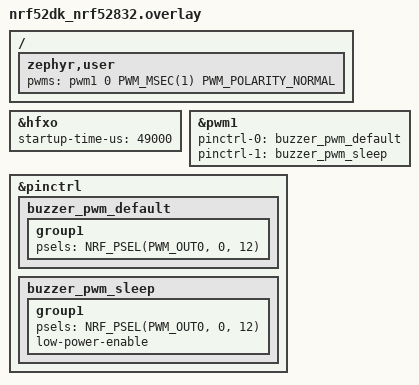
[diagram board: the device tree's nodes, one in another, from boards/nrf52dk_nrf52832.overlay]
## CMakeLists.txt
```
#
# Copyright (c) 2018 Nordic Semiconductor
#
# SPDX-License-Identifier: LicenseRef-Nordic-5-Clause
#
cmake_minimum_required(VERSION 3.20.0)

find_package(Zephyr REQUIRED HINTS $ENV{ZEPHYR_BASE})
project(NONE)

# NORDIC SDK APP START
target_sources(app PRIVATE
  src/main.c
  src/Beacon.c
  src/rssi_filter.c
  src/distance_manager.c
  src/buzzer.c
)

# NORDIC SDK APP END
zephyr_library_include_directories(.)
```

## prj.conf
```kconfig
#
# Copyright (c) 2018 Nordic Semiconductor
#
# SPDX-License-Identifier: LicenseRef-Nordic-5-Clause
#

# Button and LED library
CONFIG_DK_LIBRARY=y

# Bluetooth LE
CONFIG_BT=y
CONFIG_BT_PERIPHERAL=y
CONFIG_BT_SMP=y

# Standard Battery Service (Battery Service 0x180F / Battery Level 0x2A19).
# The Zephyr built-in implementation is used rather than a hand-written set of
# GATT attributes: the service is defined in
# zephyr/subsys/bluetooth/services/bas/bas.c:75-93 and mounted automatically by
# SYS_INIT (same file, :140), so the application only has to call
# bt_bas_set_battery_level(). The payoff is that Battery Level carries the READ
# property -- a phone can read it without subscribing -- and nRF Connect shows
# "Battery Service / Battery Level" instead of "Unknown Characteristic".
CONFIG_BT_BAS=y

# RSSI queries. Under the SoftDevice Controller the dispatch of HCI Read RSSI
# (opcode 0x1405) is gated on this symbol: with it off the opcode falls through
# to the default branch and the controller answers BT_HCI_ERR_UNKNOWN_CMD, so
# every bt_hci_cmd_send_sync() call fails.
# Evidence: nrf/subsys/bluetooth/controller/hci_internal.c:932-944 (command
# dispatch) and :371-372 in the same file (hci_read_rssi in the supported-
# commands bitmap reported to the host).
# The symbol defaults to off and must be set explicitly; changing it requires a
# full rebuild so the SDC glue is recompiled.
CONFIG_BT_CTLR_CONN_RSSI=y

# Fixed pairing passkey, supplied by CONFIG_BT_APP_PASSKEY plus the
# bt_conn_auth_cb.app_passkey callback. The older route,
# CONFIG_BT_FIXED_PASSKEY + bt_passkey_set(), is deprecated. The two are mutually
# exclusive (BT_APP_PASSKEY depends on !BT_FIXED_PASSKEY), so this is a whole-
# or-nothing replacement.
CONFIG_BT_APP_PASSKEY=y
CONFIG_BT_DEVICE_NAME="Tracker Beacon"

# Enable PHY updates.
CONFIG_BT_USER_PHY_UPDATE=y

# ADC enable.
CONFIG_NRFX_SAADC=y

# Increase stack size for the main thread and the system workqueue.
CONFIG_SYSTEM_WORKQUEUE_STACK_SIZE=2048
CONFIG_MAIN_STACK_SIZE=2048
CONFIG_BT_RX_STACK_SIZE=2048

# Data Length and MTU
CONFIG_BT_USER_DATA_LEN_UPDATE=y
CONFIG_BT_CTLR_DATA_LENGTH_MAX=251
CONFIG_BT_BUF_ACL_RX_SIZE=251
CONFIG_BT_BUF_ACL_TX_SIZE=251
CONFIG_BT_L2CAP_TX_MTU=247
CONFIG_BT_GATT_CLIENT=y

# Reboot on disconnect: the translation unit implementing sys_reboot() is only
# compiled in when CONFIG_REBOOT=y (zephyr/lib/os/CMakeLists.txt).
CONFIG_REBOOT=y

# Power management.
CONFIG_PM=y
CONFIG_PM_DEVICE=y
CONFIG_PM_DEVICE_RUNTIME=y

# The buzzer is driven through PWM. Only the PWM subsystem has to be enabled:
# CONFIG_PWM_NRFX is selected automatically from the devicetree, because its
# Kconfig says "default y / depends on DT_HAS_NORDIC_NRF_PWM_ENABLED" and the
# board overlay sets pwm1 to okay.
CONFIG_PWM=y

# MPSL assertion handling. The default implementation truncates the file name to
# 10 characters, printk()s it to the UART and calls k_oops(); on this board UART0
# is not routed to the J-Link VCOM, so that message is never seen. With this
# enabled the application-supplied mpsl_assert_handle(file, line) takes over and
# receives the full path and line number (see main.c).
CONFIG_MPSL_ASSERT_HANDLER=y
```

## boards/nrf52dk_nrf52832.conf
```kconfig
#
# nRF52 DK (nRF52832) board configuration
#

# ---------------------------------------------------------------------------
# Console
# ---------------------------------------------------------------------------
# The nRF52 DK has an on-board VCOM, and the console uses UART0 (P0.06 TX /
# P0.08 RX), which the board's nrf52dk_nrf52832_defconfig already provides:
#     CONFIG_SERIAL=y  CONFIG_CONSOLE=y  CONFIG_UART_CONSOLE=y
# Nothing here needs to redirect the console to USB CDC ACM: the nRF52832 has no
# USB peripheral at all, so such an overlay would fail devicetree parsing.
CONFIG_UART_INTERRUPT_DRIVEN=y

# ---------------------------------------------------------------------------
# Battery monitoring: the nrfx SAADC driver (CONFIG_NRFX_SAADC lives in prj.conf).
# CONFIG_ADC must stay off, or Zephyr's adc_nrfx_saadc.c would contend with the
# hand-written nrfx_saadc_init() in main.c for the same peripheral (double
# IRQ_CONNECT, double init).
# ---------------------------------------------------------------------------

# ---------------------------------------------------------------------------
# Logging: deliberately off
# ---------------------------------------------------------------------------
# CONFIG_LOG is not enabled: the project does not use the log subsystem, and on an
# nRF52832 with 64 KB of RAM it would only consume space. printk() goes to the
# console directly and needs none of it. Uncomment the three lines below to turn
# logging on while debugging.
#
# CONFIG_LOG=y
# CONFIG_LOG_MODE_DEFERRED=y
# CONFIG_LOG_BACKEND_UART=y
```

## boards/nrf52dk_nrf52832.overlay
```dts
/*
 * Board devicetree corrections: HFXO cold-start time.
 *
 * This board's 32 MHz crystal takes roughly 24.5 ms between TASKS_HFCLKSTART and
 * EVENTS_HFCLKSTARTED, while the SoC devicetree declares 1400 us.
 *
 * MPSL uses that value as the upper bound on how long it is willing to wait after
 * requesting HFCLK:
 *   z_nrf_clock_bt_ctlr_hf_get_startup_time_us()
 *       -> DT_PROP(DT_NODELABEL(hfxo), startup_time_us)   [clock_control_nrf.c:451-454]
 *   mpsl_clock_hfclk_latency_set(...)                     [mpsl/init/mpsl_init.c:457]
 * With 1400 us far below the real 24.5 ms, MPSL gives up waiting and raises
 * "MPSL ASSERT: 5, 1013"; advertising never starts.
 *
 * Where 49000 us comes from (NCS's own Kconfig text,
 * nrf/subsys/mpsl/init/Kconfig:91-96):
 *   "measure the startup time. Set MPSL_HFCLK_LATENCY as twice this number
 *    to account for temperature and supply variations.
 *    On nRF52 and nRF53 Series devices, the startup time corresponds
 *    to the time between TASKS_HFCLKSTART and EVENTS_HFCLKSTARTED."
 *   -> 2 x 24500 us = 49000 us
 *
 * CONFIG_MPSL_HFCLK_LATENCY in prj.conf is not an alternative: the nRF52832
 * devicetree does have an hfxo node, so mpsl_init.c:456 and mpsl_clock_ctrl.c:561
 * take the devicetree branch and that Kconfig symbol is bypassed entirely on this
 * platform.
 *
 * startup_time_us is a uint16_t in MPSL (mpsl_clock.h:439), so the ceiling is
 * 65535 us; 49000 is within range.
 */
&hfxo {
	startup-time-us = <49000>;
};

/*
 * Buzzer on P0.12 (active HIGH), driven by PWM1 channel 0.
 *
 * Polarity is active HIGH, not active LOW, as the schematic confirms: the MCU pin
 * drives the base of NPN transistor Q1 (2N3904) through R11, with R12 10K pulling
 * the base to ground; emitter to ground, collector to the buzzer LS1 and then
 * VCC3.3. That is a classic low-side switch:
 *   base high -> Q1 conducts -> collector pulled to ground -> 3.3 V across the
 *                buzzer -> sound
 *   base low  -> Q1 off -> no current -> silent
 * So pin high = sound and pin low = silence.
 *
 * Why PWM rather than GPIO: the requirement asks for the alarm rhythm to be
 * produced through the Zephyr PWM API, and it keeps open the option of swapping in
 * a *passive* buzzer later by driving a 2..4 kHz square wave directly -- GPIO
 * cannot produce a square wave, PWM can. This board carries an *active* buzzer:
 * it has its own oscillator, so neither the frequency nor the duty cycle of the
 * waveform changes its pitch, and PWM is used here only to express "sound / no
 * sound" plus the rhythm. See buzzer.c for the driver-level constraints.
 *
 * Why pwm1 and not pwm0: the board DTS (nrf52dk_nrf52832.dts:196-201) already
 * enables pwm0 and hands it to pwmleds (P0.17). pwm1 is disabled by default and
 * is enabled here, so the two do not interfere.
 *
 * P0.12 can only have one owner, which is why this file declares no buzzer-gpios
 * and main.c configures no GPIO for it: otherwise GPIO and PWM would drive the
 * same pin at once.
 *
 * The pinctrl groups mirror the board's pwm0 (nrf52dk_nrf52832-pinctrl.dtsi:61-73)
 * except for nordic,invert, which must NOT be copied:
 *   default -- the pin is configured as an OUTPUT with a LOW idle level
 *     (pinctrl_nrf.c:337-341 sets dir to OUTPUT, :575-577 writes the result of
 *     NRF_GET_INVERT; without nordic,invert that is a low level). For this board's
 *     active-high buzzer, idle low means silent, which is exactly the wanted
 *     power-on state. Adding the property would pull the base high the moment
 *     pinctrl is applied and produce a chirp.
 *   sleep -- low-power-enable forces the pin to an INPUT and disconnects it (same
 *     file :580-583). The base is then pulled to ground by R12 and Q1 is off, so
 *     it stays silent while asleep too.
 *
 * The driver has a build-time check, NRF_DT_CHECK_NODE_HAS_PINCTRL_SLEEP
 * (pwm_nrfx.c:416), so pinctrl-1 plus "sleep" is mandatory, not just default.
 */
&pwm1 {
	status = "okay";
	pinctrl-0 = <&buzzer_pwm_default>;
	pinctrl-1 = <&buzzer_pwm_sleep>;
	pinctrl-names = "default", "sleep";
};

&pinctrl {
	buzzer_pwm_default: buzzer_pwm_default {
		group1 {
			/* nordic,invert is deliberately absent here: an active-high
			 * buzzer needs a LOW idle level. */
			psels = <NRF_PSEL(PWM_OUT0, 0, 12)>;
		};
	};

	buzzer_pwm_sleep: buzzer_pwm_sleep {
		group1 {
			psels = <NRF_PSEL(PWM_OUT0, 0, 12)>;
			low-power-enable;
		};
	};
};

/ {
	zephyr,user {
		/* The property name must be an unprefixed pwms, not buzzer-pwms.
		 * Of all property kinds only gpio and io-channel are exempt from
		 * the prefix rule (edtlib.py:2072-2085); everything else uses
		 * prop.name[:-1] as the specifier space, so buzzer-pwms would
		 * demand a #buzzer-pwm-cells declaration from the controller --
		 * and pwm1 in nrf52832.dtsi:449 only has the standard
		 * #pwm-cells = <3>. dtc would fail outright with
		 * "lacks #buzzer-pwm-cells". (That is also why an earlier
		 * buzzer-gpios could carry a prefix.)
		 *
		 * The polarity is PWM_POLARITY_NORMAL because the buzzer is
		 * active high (low-side NPN):
		 *   0% duty   -> constant INACTIVE level -> pin low  -> silent
		 *   100% duty -> constant ACTIVE level   -> pin high -> sound
		 * That contract is written down in pwm.h:596-599, and the driver
		 * matches it in pwm_nrfx.c:199-207 and :238-249; it is not an
		 * invention of this project.
		 *
		 * PWM_POLARITY_INVERTED must NOT be used: it would treat
		 * active-high hardware as active low, so writing "silent" would
		 * drive the pin high and sound the buzzer continuously. It has to
		 * be omitted in both places -- the pinctrl group above and here --
		 * since removing only one leaves the other still inverting.
		 *
		 * The polarity cell cannot be omitted: pwm1 has
		 * #pwm-cells = <3> (nrf52832.dtsi:449), so channel, period and
		 * flags are all required after the phandle or dtc reports
		 * "missing data after phandle". PWM_POLARITY_NORMAL is 0
		 * (dt-bindings/pwm/pwm.h), i.e. "do not invert".
		 *
		 * The period is 1 ms (16000 cycles of 16 MHz, below the COUNTERTOP
		 * ceiling of 32767). In DC mode (0% / 100%) the driver never
		 * validates the period at all; a legal value is given so that
		 * producing a real 2..4 kHz square wave later needs only a period
		 * change here, with no module code touched. */
		pwms = <&pwm1 0 PWM_MSEC(1) PWM_POLARITY_NORMAL>;
	};
};
```

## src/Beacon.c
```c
/*
 * Copyright (c) 2018 Nordic Semiconductor ASA
 *
 * SPDX-License-Identifier: LicenseRef-Nordic-5-Clause
 */

#include <zephyr/types.h>
#include <stddef.h>
#include <errno.h>
#include <zephyr/kernel.h>
#include <zephyr/bluetooth/bluetooth.h>
#include <zephyr/bluetooth/conn.h>
#include <zephyr/bluetooth/uuid.h>
#include <zephyr/bluetooth/gatt.h>

#include "Beacon.h"

static bool indicate_enabled;
static bool button_state;
static struct my_lbs_cb lbs_cb;

/* ==================== The "password" behind the lost-item ring ====================
 *
 * The passkey is NOT stored by this file: it is the *link-layer pairing
 * passkey*, supplied by auth_app_passkey() in main.c. Of the writable
 * characteristics, only the Ring one carries BT_GATT_PERM_WRITE_AUTHEN. The LED
 * one carries plain BT_GATT_PERM_WRITE on purpose: switching the LED must not
 * trigger pairing, because pairing is what arms the buzzer.
 *
 * For the Ring characteristic, gatt.c:3105-3109 (NCS v3.4.0) says of the
 * authentication permission mask:
 *
 *     if (mask & BT_GATT_PERM_AUTHEN_MASK) {
 *             if (bt_conn_get_security(conn) < BT_SECURITY_L3) {
 *                     return BT_ATT_ERR_AUTHENTICATION;
 *             }
 *     }
 *
 * In other words write_ring() is invoked only while the link is authenticated
 * (>= L3). If the peer has not paired yet, the stack answers with an
 * authentication error, the phone prompts for the passkey, and once pairing
 * completes att_req_retry() (att.c:3306-3315) resends the same request -- which
 * is why the user sees "enter the passkey and the write just succeeds" without
 * tapping twice.
 *
 * Note that pairing is per *link*, not per characteristic: once the peer pairs
 * for the Ring characteristic, every AUTHEN attribute on that link is usable.
 * The LED does not use a second password; it is simply outside the gate.
 *
 * So write_ring() does not need a lock check of its own. It also does not
 * interpret the value beyond 0/1: main.c decides that 1 rings and re-arms the
 * buzzer while 0 stops the ring and mutes all alarms.
 *
 * Concrete link-layer line numbers drift between SDK releases; they are quoted
 * here against nRF Connect SDK v3.4.0. */

static struct bt_gatt_indicate_params ind_params;

static void mylbsbc_ccc_cfg_changed(const struct bt_gatt_attr *attr, uint16_t value)
{
	indicate_enabled = (value == BT_GATT_CCC_INDICATE);
}

/* Called once a remote device has acknowledged the indication at its host layer. */

static void indicate_cb(struct bt_conn *conn, struct bt_gatt_indicate_params *params, uint8_t err)
{
	ARG_UNUSED(conn);
	ARG_UNUSED(params);
	ARG_UNUSED(err);
}

static ssize_t write_led(struct bt_conn *conn, const struct bt_gatt_attr *attr, const void *buf,
			 uint16_t len, uint16_t offset, uint8_t flags)
{
	ARG_UNUSED(conn);
	ARG_UNUSED(attr);
	ARG_UNUSED(flags);

	if (len != 1U) {
		return BT_GATT_ERR(BT_ATT_ERR_INVALID_ATTRIBUTE_LEN);
	}

	if (offset != 0) {
		return BT_GATT_ERR(BT_ATT_ERR_INVALID_OFFSET);
	}

	if (lbs_cb.led_cb) {
		uint8_t val = *((uint8_t *)buf);

		if (val == 0x00 || val == 0x01) {
			lbs_cb.led_cb(val ? true : false);
		} else {
			return BT_GATT_ERR(BT_ATT_ERR_VALUE_NOT_ALLOWED);
		}
	}

	return len;
}

/* Write the ring switch (one byte, 0 or 1).
 *
 * 1 = start the lost-item ring and re-arm the buzzer; 0 = stop the ring and
 * mute every alarm, including the automatic RSSI distance beeping, until a 1
 * is written again. The application-side latch lives in main.c, so this layer
 * stays free of buzzer knowledge.
 *
 * There is deliberately no "is it unlocked" test here. The characteristic's
 * permission is BT_GATT_PERM_WRITE_AUTHEN, and gatt.c:3105-3109 guarantees such
 * a write callback runs only when bt_conn_get_security(conn) >=
 * BT_SECURITY_L3, i.e. the peer has paired and authenticated. Reaching this
 * function therefore already means the passkey was accepted; testing it again
 * would be redundant. See the comment block at the top of this file. */
static ssize_t write_ring(struct bt_conn *conn, const struct bt_gatt_attr *attr, const void *buf,
			  uint16_t len, uint16_t offset, uint8_t flags)
{
	uint8_t val;

	ARG_UNUSED(conn);
	ARG_UNUSED(attr);
	ARG_UNUSED(flags);

	if (offset != 0U) {
		return BT_GATT_ERR(BT_ATT_ERR_INVALID_OFFSET);
	}

	if (len != 1U) {
		return BT_GATT_ERR(BT_ATT_ERR_INVALID_ATTRIBUTE_LEN);
	}

	val = *(const uint8_t *)buf;
	if (val > 1U) {
		return BT_GATT_ERR(BT_ATT_ERR_VALUE_NOT_ALLOWED);
	}

	if (lbs_cb.ring_cb) {
		lbs_cb.ring_cb(val ? true : false);
	}

	return (ssize_t)len;
}

static ssize_t read_button(struct bt_conn *conn, const struct bt_gatt_attr *attr, void *buf,
			   uint16_t len, uint16_t offset)
{
	/* attr->user_data points at button_state, the pointer handed to
	 * BT_GATT_CHARACTERISTIC(..., &button_state). It is taken as a bool* and
	 * not a char* so that sizeof(*value) matches the type: both are 1 today,
	 * so the number of bytes on the wire is unchanged, but this removes the
	 * trap where a change of type for button_state would silently truncate.
	 */
	const bool *value = attr->user_data;

	if (lbs_cb.button_cb) {
		button_state = lbs_cb.button_cb();
		return bt_gatt_attr_read(conn, attr, buf, len, offset, value, sizeof(*value));
	}

	return 0;
}

/* LED Button Service Declaration */
BT_GATT_SERVICE_DEFINE(
	my_lbs_svc, BT_GATT_PRIMARY_SERVICE(BT_UUID_LBS),
	BT_GATT_CHARACTERISTIC(BT_UUID_LBS_BUTTON, BT_GATT_CHRC_READ | BT_GATT_CHRC_INDICATE,
			       BT_GATT_PERM_READ_AUTHEN, read_button, NULL, &button_state),
	BT_GATT_CCC(mylbsbc_ccc_cfg_changed, BT_GATT_PERM_READ | BT_GATT_PERM_WRITE),

	/* LED characteristic. Deliberately BT_GATT_PERM_WRITE rather than
	 * ..._AUTHEN: writing it must not trigger pairing, because the pairing
	 * passkey is the buzzer's unlock (…1528). With AUTHEN here, a user who
	 * only wanted to switch the LED would pair as a side effect, and
	 * on_security_changed() would arm the distance alarm at the same moment.
	 */
	BT_GATT_CHARACTERISTIC(BT_UUID_LBS_LED, BT_GATT_CHRC_WRITE, BT_GATT_PERM_WRITE, NULL,
			       write_led, NULL),

	/* RSSI characteristic: notify only, value is a signed 8-bit dBm reading,
	 * so the value attribute is PERM_NONE -- a phone subscribes by writing
	 * the CCC rather than reading the attribute directly.
	 *
	 * New characteristics are always appended at the END of the service so
	 * that the indices of the attributes above never move. That is what keeps
	 * the hard-coded attrs[2] in my_lbs_send_button_state_indicate() (the
	 * Button characteristic value) valid; the RSSI block occupies [6]
	 * declaration, [7] value, [8] CCC, [9] CUD.
	 *
	 * The CUD descriptor gives the phone a readable label: BLE
	 * characteristics have no "name" field, so a client can only derive a
	 * display name by looking the UUID up in its built-in table, and 0x1526
	 * is a private number that no such table contains.
	 */
	BT_GATT_CHARACTERISTIC(BT_UUID_LBS_RSSI, BT_GATT_CHRC_NOTIFY, BT_GATT_PERM_NONE, NULL, NULL,
			       NULL),
	/* Passing NULL as the CCC's cfg_changed is legal: gatt.c:2076 and :3325
	 * both check for NULL before calling. This service does not need to track
	 * its own subscription state -- whether a value should be sent is decided
	 * by the host from the CCC (gatt.c:2401-2410).
	 */
	BT_GATT_CCC(NULL, BT_GATT_PERM_READ | BT_GATT_PERM_WRITE),
	BT_GATT_CUD("RSSI (dBm)", BT_GATT_PERM_READ),

	/* Ring control characteristic, appended at the end for the same
	 * index-stability reason as above: nothing in [0]..[9] moves, so attrs[2]
	 * stays valid. This characteristic occupies [10] declaration,
	 * [11] value, [12] CUD.
	 *
	 * The permission is BT_GATT_PERM_WRITE_AUTHEN, which is how "pair with
	 * the device and enter the passkey before you can start the lost-item
	 * ring" is implemented: the passkey lives at the link layer, supplied by
	 * auth_app_passkey() in main.c. Writing 0 needs the same authentication
	 * and is the only way to mute the distance alarm, so the gate also covers
	 * "silence everything".
	 *
	 * It carries a CUD because 0x1528 is a private UUID that no phone's
	 * characteristic lookup table contains -- without the descriptor it would
	 * show up as "Unknown Characteristic".
	 */
	BT_GATT_CHARACTERISTIC(BT_UUID_LBS_RING, BT_GATT_CHRC_WRITE, BT_GATT_PERM_WRITE_AUTHEN, NULL,
			       write_ring, NULL),
	BT_GATT_CUD("Ring Control (1 = ring, 0 = mute all) - pair first", BT_GATT_PERM_READ),
);
/* A function to register application callbacks for the LED and Button characteristics  */
int my_lbs_init(struct my_lbs_cb *callbacks)
{
	if (callbacks) {
		lbs_cb.led_cb = callbacks->led_cb;
		lbs_cb.ring_cb = callbacks->ring_cb;
		lbs_cb.button_cb = callbacks->button_cb;
	}

	return 0;
}

int my_lbs_send_button_state_indicate(bool button_state)
{
	if (!indicate_enabled) {
		return -EACCES;
	}
	ind_params.attr = &my_lbs_svc.attrs[2];
	ind_params.func = indicate_cb; // A remote device has ACKed at its host layer (ATT ACK)
	ind_params.destroy = NULL;
	ind_params.data = &button_state;
	ind_params.len = sizeof(button_state);
	return bt_gatt_indicate(NULL, &ind_params);
}

int my_lbs_send_rssi_notify(int8_t rssi)
{
	/* bt_gatt_notify_uuid() looks the characteristic up by UUID instead of
	 * hard-coding attrs[n], so characteristics can be added to or removed
	 * from this service without getting an index wrong. attrs[0] is the
	 * service declaration, whose position is fixed, and serves as the search
	 * origin (gatt.h:1517-1518). A NULL first argument means "notify every
	 * peer that has enabled the CCC".
	 */
	int rc = bt_gatt_notify_uuid(NULL, BT_UUID_LBS_RSSI, &my_lbs_svc.attrs[0], &rssi,
				     sizeof(rssi));

	/* "Nobody subscribed" (with CONFIG_BT_GATT_ENFORCE_SUBSCRIPTION=y the host
	 * reports -EINVAL, see gatt.c:2401-2410) and "nobody connected"
	 * (-ENOTCONN, gatt.c:2812) are both normal states for a periodic sender,
	 * so reporting 0 rather than an error is deliberate -- the same
	 * normalisation bas.c:129 applies to -ENOTCONN. */
	if (rc == -EINVAL || rc == -ENOTCONN) {
		return 0;
	}

	return rc;
}
```

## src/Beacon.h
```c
/*
 * Copyright (c) 2018 Nordic Semiconductor ASA
 *
 * SPDX-License-Identifier: LicenseRef-Nordic-5-Clause
 */

#ifndef BT_LBS_H_
#define BT_LBS_H_

/**@file
 * @defgroup bt_lbs LED Button Service API
 * @{
 * @brief API for the LED Button Service (LBS).
 */

#ifdef __cplusplus
extern "C" {
#endif

#include <zephyr/types.h>

/** @brief LBS Service UUID. */
#define BT_UUID_LBS_VAL BT_UUID_128_ENCODE(0x00001523, 0x1212, 0xefde, 0x1523, 0x785feabcd123)

/** @brief Button Characteristic UUID. */
#define BT_UUID_LBS_BUTTON_VAL                                                                     \
	BT_UUID_128_ENCODE(0x00001524, 0x1212, 0xefde, 0x1523, 0x785feabcd123)

/** @brief LED Characteristic UUID. */
#define BT_UUID_LBS_LED_VAL BT_UUID_128_ENCODE(0x00001525, 0x1212, 0xefde, 0x1523, 0x785feabcd123)

#define BT_UUID_LBS BT_UUID_DECLARE_128(BT_UUID_LBS_VAL)
#define BT_UUID_LBS_BUTTON BT_UUID_DECLARE_128(BT_UUID_LBS_BUTTON_VAL)
#define BT_UUID_LBS_LED BT_UUID_DECLARE_128(BT_UUID_LBS_LED_VAL)

/** @brief RSSI Characteristic UUID.
 *  Follows the service's existing base UUID with the first field taken one step
 *  further, from 0x1525 to 0x1526. This is a private UUID (not a Bluetooth SIG
 *  assigned number), so a phone has no name to look it up under and will most
 *  likely show it as "Unknown Characteristic"; the CUD descriptor attached to
 *  the characteristic is what gives it a readable label. */
#define BT_UUID_LBS_RSSI_VAL                                                                       \
	BT_UUID_128_ENCODE(0x00001526, 0x1212, 0xefde, 0x1523, 0x785feabcd123)

#define BT_UUID_LBS_RSSI BT_UUID_DECLARE_128(BT_UUID_LBS_RSSI_VAL)
/** @brief Ring control Characteristic UUID (a single byte is written, 0 or 1).
 *
 *  The permission is BT_GATT_PERM_WRITE_AUTHEN, so a phone must finish pairing
 *  (entering the passkey) before it can write here. Once pairing completes,
 *  att_req_retry() (att.c:3306-3315 in NCS v3.4.0) resends the pending request
 *  automatically, so the user does not have to tap a second time. */
#define BT_UUID_LBS_RING_VAL                                                                       \
	BT_UUID_128_ENCODE(0x00001528, 0x1212, 0xefde, 0x1523, 0x785feabcd123)

#define BT_UUID_LBS_RING BT_UUID_DECLARE_128(BT_UUID_LBS_RING_VAL)

/** @brief Callback type for when an LED state change is received. */
typedef void (*led_cb_t)(const bool led_state);

/** @brief Callback type for when a ring (buzzer) state change is received.
 *
 *  Kept separate from led_cb because switching a LED and sounding the buzzer are
 *  two distinct pieces of hardware: the LED goes through dk_set_led on DK_LED4
 *  (P0.20), the buzzer through PWM1 channel 0 (P0.12). Characteristic ...1525
 *  drives only the LED and ...1528 only the buzzer; neither touches the other,
 *  so "turn the LED on" can never make a sound.
 *
 *  ring_state = true starts the manual ring; false stops it and also mutes the
 *  automatic distance alarm until the next true. */
typedef void (*ring_cb_t)(const bool ring_state);

/** @brief Callback type for when the button state is pulled. */
typedef bool (*button_cb_t)(void);

/** @brief Callback struct used by the LBS Service. */
struct my_lbs_cb {
	/** LED state change callback. */
	led_cb_t led_cb;
	/** Ring state change callback. */
	ring_cb_t ring_cb;
	/** Button read callback. */
	button_cb_t button_cb;
};

/** @brief Initialize the LBS Service.
 *
 * This function registers application callback functions with the My LBS
 * Service
 *
 * @param[in] callbacks Struct containing pointers to callback functions
 *			used by the service. This pointer can be NULL
 *			if no callback functions are defined.
 *
 *
 * @retval 0 If the operation was successful.
 *           Otherwise, a (negative) error code is returned.
 */
int my_lbs_init(struct my_lbs_cb *callbacks);

/** @brief Send the button state as indication.
 *
 * This function sends a binary state, typically the state of a
 * button, to all connected peers.
 *
 * @param[in] button_state The state of the button.
 *
 * @retval 0 If the operation was successful.
 *           Otherwise, a (negative) error code is returned.
 */
int my_lbs_send_button_state_indicate(bool button_state);

/** @brief Send the connection RSSI over the RSSI characteristic.
 *
 * Sends the dBm value as a signed 8-bit number to every peer that has enabled
 * the characteristic's CCC.
 *
 * @param[in] rssi RSSI value (dBm, normally negative).
 *
 * @retval 0 on success. Also 0 when no peer is subscribed or none is connected
 *           -- that is a no-op, not a failure.
 *         Any other negative value is a real error code.
 */
int my_lbs_send_rssi_notify(int8_t rssi);

#ifdef __cplusplus
}
#endif

/**
 * @}
 */

#endif /* BT_LBS_H_ */
```

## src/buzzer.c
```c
/*
 * Buzzer control module -- implementation.
 *
 * ==================== Approach ====================
 *
 * The output level is produced by a PWM channel; the rhythm is produced by a
 * k_timer. Each does one job:
 *
 *   PWM     -> should this pin be "active" or "inactive" right now (i.e. sound
 *              or not sound)
 *   k_timer -> when to flip it
 *
 * Why not PWM alone: the nRF52 PWM peripheral tops out at a period of roughly
 * 262 ms (pwm_nrfx.c:101-146 -- prescaler limited to /128 and COUNTERTOP to
 * about 15 bits), which cannot express a second-scale rhythm such as "beep for
 * 60 ms, wait 3 s" in a single configuration.
 *
 * Why not GPIO alone: the requirement is to drive the buzzer through the Zephyr
 * PWM API, which also keeps the door open for a future *passive* buzzer -- that
 * would only need the duty cycle changed to a 50% square wave at 2..4 kHz, with
 * no other code touched.
 *
 * ==================== Why PWM can act as a plain switch ====================
 *
 * This is not a trick; it is part of the PWM subsystem's contract. pwm.h:596-599
 * states:
 *
 *     Passing 0 as @p pulse will cause the pin to be driven to a constant
 *     inactive level.
 *     Passing a non-zero @p pulse equal to @p period will cause the pin to be
 *     driven to a constant active level.
 *
 * The driver matches that (pwm_nrfx.c:199-207): a pulse of 0 or >= period
 * resolves to a constant compare value, and only the genuine intermediate
 * waveform path calls pwm_period_check_and_set(); afterwards :238-249 writes the
 * pin level through nrf_gpio_pin_write() as if it were an ordinary GPIO.
 *
 * That distinction matters here: the period check is never reached, so this
 * module is not bound by the 262 ms limit, and the busy-wait
 * `while (!nrfx_pwm_stopped_check(...))` at pwm_nrfx.c:280 is never reached
 * either (it only runs while pwm_needed != 0). This module can therefore call
 * pwm_set_dt() safely from a k_timer interrupt callback.
 *
 * ==================== About the buzzer being active ====================
 *
 * This board carries an *active* buzzer: it has its own internal oscillator and
 * sounds as soon as it sees a DC level. Neither the frequency nor the duty cycle
 * of a PWM wave changes its pitch or volume, so this module uses PWM only to
 * express "sound / silence" and the rhythm.
 *
 * ==================== Polarity ====================
 *
 * The buzzer on this board is *active high*. Schematic: the MCU pin drives the
 * base of NPN transistor Q1 (2N3904) through R11, with R12 10K pulling the base
 * to ground; emitter to ground, collector to the buzzer and then VCC3.3. That is
 * a classic low-side switch -- the base must be driven high for current to flow.
 *
 * The devicetree `pwms` entry carries no PWM_POLARITY_INVERTED and the pinctrl
 * group carries no nordic,invert, so:
 *   duty 0%   -> constant inactive level -> pin low  -> silent
 *   duty 100% -> constant active level   -> pin high -> sounding
 * which lines up one-to-one with buzzer_write(false) / (true) below.
 */

#include "buzzer.h"

#include <zephyr/device.h>
#include <zephyr/drivers/pwm.h>
#include <zephyr/kernel.h>
#include <zephyr/pm/device_runtime.h>
#include <zephyr/sys/util.h>

/* Take the pwms entry from zephyr,user in the devicetree
 * (boards/nrf52dk_nrf52832.overlay). zephyr,user exists to carry arbitrary
 * properties that have no binding of their own.
 *
 * The property name must not carry a bus prefix: unlike gpio, PWM does not
 * ignore a prefix during parsing. A name such as buzzer-pwms would be treated as
 * a different specifier space and dtc would demand a #buzzer-pwm-cells
 * declaration. See the overlay for the full explanation.
 */
static const struct pwm_dt_spec buzzer_pwm = PWM_DT_SPEC_GET(DT_PATH(zephyr_user));

/* Which rhythm a manual ring uses. FAST was chosen because locating a lost item
 * benefits from an immediately identifiable sound.
 */
#define BUZZER_RING_PATTERN BUZZER_FAST

/* Rhythm table: how long to sound (on_ms) and how long to stay quiet (off_ms).
 *
 * SILENT and CONTINUOUS do not use this table -- they have no "flip" concept and
 * are written directly as a level by buzzer_apply(). Their 0/0 rows exist only
 * to keep the array indexed by the enum; the timer callback still carries a
 * defensive check against them (see buzzer_timer_handler).
 *
 * Why the NORMAL grade is silent: the requirement names four grades
 * (near / normal / far / lost) but never says what "normal" should sound like.
 * Staying quiet is the more conservative default; this one line is all that
 * needs to change to get a very slow short beep instead.
 */
struct buzzer_step {
	uint16_t on_ms;
	uint16_t off_ms;
};

static const struct buzzer_step buzzer_steps[] = {
	[BUZZER_SILENT]     = { .on_ms = 0U,   .off_ms = 0U    },
	[BUZZER_SLOW]       = { .on_ms = 60U,  .off_ms = 3000U },
	[BUZZER_FAST]       = { .on_ms = 200U, .off_ms = 400U  },
	[BUZZER_CONTINUOUS] = { .on_ms = 0U,   .off_ms = 0U    },
};

/* ---- State ---- */
/* master switch: link authenticated and not muted by a Ring 0 write */
static bool buzzer_enabled;
static enum buzzer_pattern dist_pattern;	/* request from the distance side */
static bool ring_requested;			/* manual ring request */

/* The rhythm currently running. Kept separate from the "target rhythm" so the
 * code can tell whether anything needs changing: an unchanged rhythm must not
 * restart the timer, or a once-per-second call would keep cutting off a
 * long-interval rhythm.
 */
static enum buzzer_pattern running_pattern = BUZZER_SILENT;

/* Whether the current rhythm is in its "sound" or its "quiet" phase. */
static bool phase_on;

/* ---- Diagnostic mirrors (not static -- see the same note in rssi_filter.c) ----
 * printk is invisible on this board, so reading these out of RAM shows what the
 * buzzer module actually decided.
 */
int32_t g_buzzer_enabled;
int32_t g_buzzer_target;	/* rhythm chosen by buzzer_effective_pattern() */
int32_t g_buzzer_on;		/* whether the pin is currently "sounding" */
int32_t g_buzzer_pwm_ret;	/* return value of the last pwm_set_dt() */

static void buzzer_timer_handler(struct k_timer *timer);

K_TIMER_DEFINE(buzzer_timer, buzzer_timer_handler, NULL);

/* Drive the pin to "sound" or "silent".
 *
 * The period passed is buzzer_pwm.period (1 ms from the devicetree). The DC
 * branch does not validate the period, but passing the same value as period and
 * pulse lands exactly on the "constant active level" contract at pwm.h:598-599,
 * which makes the intent obvious at a glance.
 */
static int buzzer_write(bool on)
{
	int ret = pwm_set_dt(&buzzer_pwm, buzzer_pwm.period,
			     on ? buzzer_pwm.period : 0U);

	g_buzzer_on = on ? 1 : 0;
	g_buzzer_pwm_ret = ret;

	return ret;
}

/* Timer expiry -> flip the phase.
 *
 * This runs in *interrupt context* (k_timer expiry functions are called from the
 * system clock ISR), so only non-blocking work is allowed. The module header
 * above argues why pwm_set_dt() does not busy-wait in the DC case.
 *
 * Note that pm_device_runtime_get() must NOT be called here -- it takes a
 * semaphore and is not interrupt-safe. Waking the device happens once, in
 * buzzer_init().
 */
static void buzzer_timer_handler(struct k_timer *timer)
{
	ARG_UNUSED(timer);

	const struct buzzer_step *step = &buzzer_steps[running_pattern];

	/* Defensive: only SLOW / FAST ever start this timer. Should the state
	 * ever be corrupted into 0/0, K_MSEC(0) would make the timer expire
	 * again immediately inside the ISR, and the device would lock up.
	 * Silence is the safer failure mode. */
	if (step->on_ms == 0U || step->off_ms == 0U) {
		running_pattern = BUZZER_SILENT;
		(void)buzzer_write(false);
		return;
	}

	phase_on = !phase_on;

	if (phase_on) {
		(void)buzzer_write(true);
		k_timer_start(&buzzer_timer, K_MSEC(step->on_ms), K_NO_WAIT);
	} else {
		(void)buzzer_write(false);
		k_timer_start(&buzzer_timer, K_MSEC(step->off_ms), K_NO_WAIT);
	}
}

/* Merge the three inputs (master switch, distance rhythm, ring request) into one
 * rhythm by priority:
 *   1. master switch off -> silent (neither distance alarm nor ring sounds);
 *      that covers "not unlocked" and "muted by a Ring 0 write"
 *   2. distance FAR/LOST -> the distance alarm rhythm
 *   3. manual ring on   -> the ring rhythm
 *   4. otherwise        -> the distance-side table (NEAR slow beep / NORMAL
 *                          silent)
 *
 * FAR/LOST is tested explicitly rather than "distance rhythm is not silent",
 * because NEAR is audible too: if NEAR outranked the ring, the ring button would
 * stop working whenever the user stood next to the device, which makes no sense.
 */
static enum buzzer_pattern buzzer_effective_pattern(void)
{
	if (!buzzer_enabled) {
		return BUZZER_SILENT;
	}

	if (dist_pattern == BUZZER_FAST || dist_pattern == BUZZER_CONTINUOUS) {
		return dist_pattern;
	}

	if (ring_requested) {
		return BUZZER_RING_PATTERN;
	}

	return dist_pattern;
}

/* Commit the target rhythm to the hardware. Touches the timer only when the
 * rhythm actually changed.
 */
static void buzzer_apply(void)
{
	enum buzzer_pattern target = buzzer_effective_pattern();

	g_buzzer_target = (int32_t)target;

	if (target == running_pattern) {
		/* Unchanged -- let the current cycle finish rather than
		 * interrupting it. This is what makes "beep 60 ms, wait 3 s"
		 * actually sound like once every 3 s, given that the RSSI
		 * thread calls buzzer_set_pattern() every second. */
		return;
	}

	running_pattern = target;
	phase_on = false;

	switch (target) {
	case BUZZER_CONTINUOUS:
		k_timer_stop(&buzzer_timer);
		(void)buzzer_write(true);
		break;

	case BUZZER_SLOW:
	case BUZZER_FAST:
		/* Start with the "sound" phase: sounding first and waiting after
		 * reads as a more immediate alarm than the reverse. */
		k_timer_stop(&buzzer_timer);
		phase_on = true;
		(void)buzzer_write(true);
		k_timer_start(&buzzer_timer, K_MSEC(buzzer_steps[target].on_ms), K_NO_WAIT);
		break;

	case BUZZER_SILENT:
	default:
		k_timer_stop(&buzzer_timer);
		(void)buzzer_write(false);
		break;
	}
}


int buzzer_init(void)
{
	if (!pwm_is_ready_dt(&buzzer_pwm)) {
		return -ENODEV;
	}

	/* The PWM device MUST be resumed, otherwise the buzzer never sounds.
	 *
	 * Why: this project enables CONFIG_PM_DEVICE_RUNTIME=y (prj.conf), and
	 *   zephyr/soc/nordic/common/Kconfig.defconfig:10-11
	 *       config PM_DEVICE_RUNTIME_DEFAULT_ENABLE
	 *           default y if PM_DEVICE_RUNTIME
	 * makes runtime PM the default for *every* device. Consequently
	 *   zephyr/subsys/pm/device.c:415-422
	 * leaves the device in PM_DEVICE_STATE_SUSPENDED inside
	 * pm_device_driver_init() and returns without calling RESUME, while
	 * pwm_nrfx.c:390-392 already applied the pinctrl sleep state during init
	 * -- P0.12 is configured as an input and disconnected
	 * (pinctrl_nrf.c:580-583).
	 *
	 * Neither the PWM driver nor pwm.h ever gets this device on its own, so
	 * without the wake-up here pwm_set_dt() reports success while the pin is
	 * not driven at all.
	 *
	 * The device is deliberately never put back: the buzzer has to be ready
	 * on demand, so it stays ACTIVE at the cost of one channel held open (the
	 * nRF52832 PWM is a separate peripheral and does not consume MPSL's
	 * RTC/TIMER). The call returns 0 harmlessly when pm == NULL or when
	 * runtime PM is not enabled for the device.
	 */
	(void)pm_device_runtime_get(buzzer_pwm.dev);

	buzzer_enabled = false;
	dist_pattern = BUZZER_SILENT;
	ring_requested = false;
	running_pattern = BUZZER_SILENT;
	phase_on = false;

	g_buzzer_enabled = 0;
	g_buzzer_target = BUZZER_SILENT;

	/* Write the silent level explicitly rather than relying on the static
	 * idle level from pinctrl, so the power-on state is guaranteed by code
	 * and not by the devicetree. */
	return buzzer_write(false);
}


void buzzer_set_enabled(bool enabled)
{
	if (enabled == buzzer_enabled) {
		return;
	}

	buzzer_enabled = enabled;
	g_buzzer_enabled = enabled ? 1 : 0;

	buzzer_apply();
}


void buzzer_set_pattern(enum buzzer_pattern pattern)
{
	if (pattern == dist_pattern) {
		return;
	}

	dist_pattern = pattern;

	buzzer_apply();
}


void buzzer_set_ring(bool on)
{
	if (on == ring_requested) {
		return;
	}

	ring_requested = on;

	buzzer_apply();
}
```

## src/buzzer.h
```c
/*
 * Buzzer control module (PWM output level + k_timer rhythm).
 *
 * Responsibility boundary: this module understands only its own
 * enum buzzer_pattern. It does not know what a "distance grade" is and does not
 * know what a "password" is. The distance side maps its grade to a pattern and
 * passes that in; the lock side passes a single boolean. As a result the module
 * can be tested on its own and is unaffected by distance-threshold tuning or by
 * changes in the unlock policy.
 */

#ifndef BUZZER_H_
#define BUZZER_H_

#include <stdbool.h>

/** @brief Alarm rhythm. */
enum buzzer_pattern {
	BUZZER_SILENT = 0,	/**< silent */
	BUZZER_SLOW,		/**< slow: an occasional short beep */
	BUZZER_FAST,		/**< fast: urgent on/off */
	BUZZER_CONTINUOUS,	/**< continuous tone */
};

/** @brief Initialise the PWM channel and drive the output to silence.
 *
 * @retval 0 on success, or a negative error code (PWM device not ready, ...).
 */
int buzzer_init(void);

/** @brief Master enable, driven by the unlock state and the Ring mute latch.
 *
 * While enabled == false everything is silent regardless of what the distance
 * side or the manual-ring side requested -- this is where "the password gates
 * the whole lost-item alarm" lands, and also where a Ring 0 write mutes the
 * automatic distance alarm. Passing the same value again is ignored, so callers
 * may simply call it once per loop iteration.
 */
void buzzer_set_enabled(bool enabled);

/** @brief Set the rhythm requested by the distance side.
 *
 * Does nothing when the request equals the current one -- otherwise a call every
 * second would keep interrupting a long-interval rhythm and "beep for 60 ms,
 * wait 3 s" would degrade to "beep once a second".
 */
void buzzer_set_pattern(enum buzzer_pattern pattern);

/** @brief Turn the manual ring request on or off. Also ignores a repeated value.
 *
 * Priority: BUZZER_CONTINUOUS / BUZZER_FAST (that is, LOST / FAR) outrank the
 * ring request. See buzzer_effective_pattern() in buzzer.c.
 */
void buzzer_set_ring(bool on);

#endif /* BUZZER_H_ */
```

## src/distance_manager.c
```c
/*
 * Distance grading module -- implementation.
 *
 * ==================== Why grade instead of compute distance ====================
 *
 * The textbook free-space path loss model is
 *     RSSI(d) = RSSI(d0) - 10*n*log10(d / d0)
 * which can in principle be inverted to solve for d. In practice nobody does
 * that, for four reasons:
 *
 * 1. RSSI does not measure distance, it measures received power. The same power
 *    reads several dB different after a change of obstacle, a turn of the body,
 *    or a hand over the antenna.
 *
 * 2. The path loss exponent n is environment-dependent: n~2 in free space, n~3
 *    in an office, n~4..6 through walls. The same device has a different n in
 *    the living room and in the stairwell, so a curve calibrated in one place is
 *    invalid in another.
 *
 * 3. RSSI quantisation is very coarse. BLE controllers report whole dBm, and
 *    the 10*log10 relationship means 10% distance accuracy would need RSSI
 *    accurate to 0.4 dB -- beyond what the radio can measure.
 *
 * 4. Worse, 10*log10(d) is logarithmic: the farther away, the less distance
 *    changes per dB. Near -50 dBm, 6 dB might mean the distance doubled; near
 *    -90 dBm, 6 dB might mean it multiplied several times. The computed distance
 *    is therefore least accurate precisely where it matters most.
 *
 * Conclusion: RSSI is good for "close / ok / far / gone" and bad for "3.7 m
 * away". This module therefore outputs a grade, not a distance.
 *
 * ==================== How the hysteresis works ====================
 *
 * All three boundaries share one algorithm instead of their own if/else:
 *
 *   For boundary i, if the current grade is already on its "far" side (that is,
 *   level > i), then crossing back to the "near" side requires beating the
 *   nominal threshold by HYST dB; otherwise the nominal threshold is used.
 *
 *   Then simply count how many boundaries the value falls outside of -- that
 *   count is the new grade.
 *
 * The benefit: the grade can still jump all the way in one step (NEAR straight
 * to LOST is not dragged out gradually), while each boundary independently
 * keeps its own backlash.
 */

#include "distance_manager.h"

static const int8_t dist_threshold[] = {
	DIST_TH_NEAR_DBM,
	DIST_TH_FAR_DBM,
	DIST_TH_LOST_DBM,
};

/* Three boundaries split the space into four grades, so the threshold count is
 * always DIST_LOST (== 3).
 */
#define DIST_THRESHOLD_COUNT 3

static enum distance_level cur_level = DIST_UNKNOWN;
static int8_t cur_rssi;

/* Diagnostic mirrors (deliberately not static -- see the same note in
 * rssi_filter.c): printk is invisible on this board, so read these out of RAM
 * to see what the module decided.
 */
int32_t g_dist_level = DIST_UNKNOWN;
int32_t g_dist_rssi;


void distance_manager_reset(void)
{
	cur_level = DIST_UNKNOWN;
	cur_rssi = 0;
	g_dist_level = DIST_UNKNOWN;
	g_dist_rssi = 0;
}


enum distance_level distance_manager_update(int8_t filtered_rssi)
{
	uint8_t below = 0U;

	for (uint8_t i = 0U; i < DIST_THRESHOLD_COUNT; i++) {
		int8_t th = dist_threshold[i];

		/* cur_level == DIST_UNKNOWN means there is no history yet, and
		 * the nominal threshold must be used. Its enumerator value is 4,
		 * larger than any i, so without this special case it would look
		 * like the value is already beyond every boundary and hysteresis
		 * would be applied to all of them at once. */
		if (cur_level != DIST_UNKNOWN && (uint8_t)cur_level > i) {
			th = (int8_t)(th + DIST_HYSTERESIS_DB);
		}

		if (filtered_rssi < th) {
			below++;
		}
	}

	/* below ranges over 0..3 and maps one-to-one onto NEAR / NORMAL / FAR /
	 * LOST. That mapping depends on the enumerator order in
	 * distance_manager.h. */
	cur_level = (enum distance_level)below;
	cur_rssi = filtered_rssi;

	g_dist_level = (int32_t)cur_level;
	g_dist_rssi = filtered_rssi;

	return cur_level;
}


const char *distance_level_str(enum distance_level lv)
{
	switch (lv) {
	case DIST_NEAR:
		return "NEAR";
	case DIST_NORMAL:
		return "NORMAL";
	case DIST_FAR:
		return "FAR";
	case DIST_LOST:
		return "LOST";
	case DIST_UNKNOWN:
	default:
		return "UNKNOWN";
	}
}
```

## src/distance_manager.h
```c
/*
 * Distance grading module.
 *
 * Responsibility boundary: this module does one thing -- "filtered dBm in, one
 * enum out". It does not know the buzzer exists, nor what an alarm rhythm looks
 * like. Turning a grade into a rhythm is main.c's job.
 */

#ifndef DISTANCE_MANAGER_H_
#define DISTANCE_MANAGER_H_

#include <stdint.h>

/** @brief Distance grade.
 *
 * The ORDER of the enumerators is significant: the hysteresis algorithm below
 * compares (uint8_t)level directly, so the values must increase strictly from
 * nearest to farthest. Inserting a new grade in the middle also requires
 * extending dist_threshold[] by one entry, or the number of thresholds and the
 * number of grades will no longer line up.
 */
enum distance_level {
	DIST_NEAR = 0,	/**< RSSI >= -50 dBm: right next to the phone */
	DIST_NORMAL,	/**< -65 .. -50 dBm: normal separation */
	DIST_FAR,	/**< -80 .. -65 dBm: getting away */
	DIST_LOST,	/**< RSSI < -80 dBm: presumed lost */
	DIST_UNKNOWN,	/**< No valid sample has ever arrived (not connected yet,
			 *   or just started). It is listed after DIST_LOST but does
			 *   NOT mean "farther than lost" -- it merely keeps the
			 *   values 0..3 cleanly mapped onto the four real grades.
			 */
};

/** @brief Boundaries between the first three grades (dBm). Entry 0 separates
 *         NEAR/NORMAL, entry 1 separates NORMAL/FAR, entry 2 separates
 *         FAR/LOST. They are the thresholds in the "moving away" direction.
 */
#define DIST_TH_NEAR_DBM (-50)
#define DIST_TH_FAR_DBM  (-65)
#define DIST_TH_LOST_DBM (-80)

/** @brief Hysteresis band (dB).
 *
 * Why it is required: RSSI dithers around a boundary (a +-5 dB swing is normal
 * in practice). With a single threshold, a device sitting near -65 dBm would
 * flip between NORMAL and FAR continuously, so the buzzer would alternate
 * between two rhythms and sound broken. The band gives the state memory: to
 * fall back from FAR to NORMAL the signal must be 3 dB stronger than what it
 * took to enter FAR.
 */
#define DIST_HYSTERESIS_DB 3

/** @brief Reset to the "no sample received yet" state. */
void distance_manager_reset(void);

/** @brief Feed a new filtered value, update the grade and return it. */
enum distance_level distance_manager_update(int8_t filtered_rssi);

/** @brief Human-readable grade name, for logging only. */
const char *distance_level_str(enum distance_level lv);

#endif /* DISTANCE_MANAGER_H_ */
```

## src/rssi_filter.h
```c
/*
 * RSSI moving-average filter.
 *
 * Responsibility boundary: this module only turns "a noisy stream of dBm values"
 * into "a smoothed stream of dBm values". It knows nothing about distance and
 * nothing about the buzzer, so it can be exercised without Bluetooth at all --
 * feed it a stream of numbers and inspect the output.
 */

#ifndef RSSI_FILTER_H_
#define RSSI_FILTER_H_

#include <stdint.h>

/** @brief Sliding-window length N (number of samples retained).
 *
 * Trade-off (counts below assume the poll period set by RSSI_POLL_INTERVAL_MS
 * in main.c, currently 100 ms):
 *   too short (e.g. 2 samples = 0.2 s)  -> barely smooths anything, a single
 *                          jittery reading passes straight through;
 *   too long (e.g. 50 samples = 5 s)    -> so sluggish that the buzzer reacts
 *                          long after the wearer has already walked away. For a
 *                          lost-item alarm, lag is more dangerous than jitter.
 * 5 samples at 100 ms is a 0.5 s observation window. Raising this to 50
 * restores the ~5 s window that was in use at the former 1 s poll rate.
 */
#define RSSI_FILTER_WINDOW 5

/** @brief Clear the filter back to the "no samples yet" state. */
void rssi_filter_init(void);

/** @brief Push one new sample and return the resulting average.
 *
 * @param[in] sample Raw RSSI for this poll (dBm, normally negative).
 *                   The caller must ensure it is a valid reading: the
 *                   controller's "not available" marker 0x7F
 *                   (BT_HCI_LE_RSSI_NOT_AVAILABLE) must never reach this
 *                   function. That check lives in read_conn_rssi() in main.c.
 *
 * @return Average RSSI over the current window (dBm). While fewer than N
 *         samples have been pushed, the average is taken over what is there,
 *         so a fresh connection yields a value immediately instead of stalling
 *         for N seconds.
 */
int8_t rssi_filter_update(int8_t sample);

#endif /* RSSI_FILTER_H_ */
```
